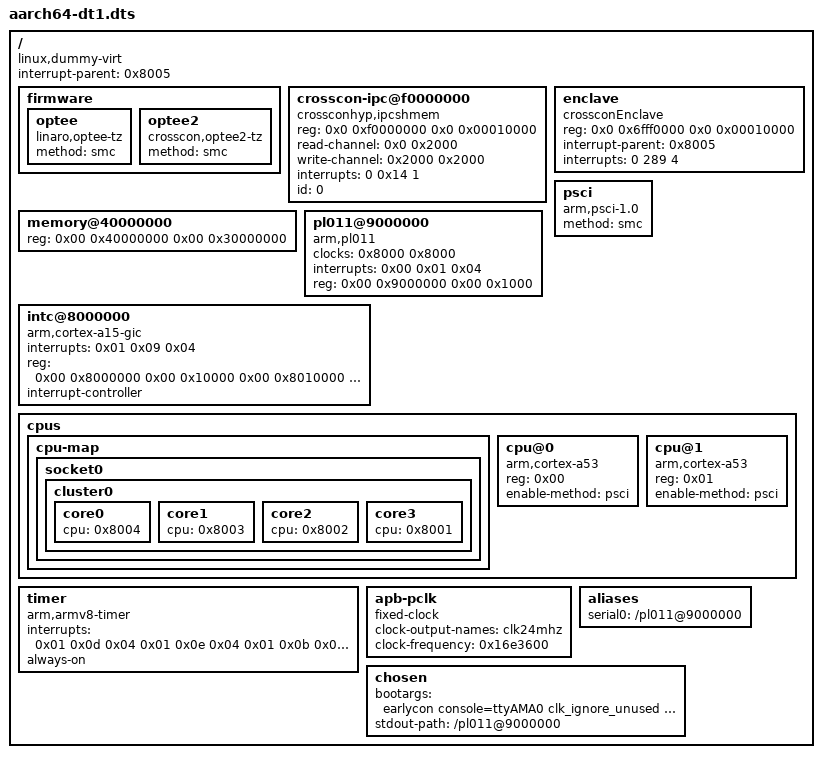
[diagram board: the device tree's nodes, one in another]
/dts-v1/;

/ {
	interrupt-parent = <0x8005>;
	#size-cells = <0x02>;
	#address-cells = <0x02>;
	compatible = "linux,dummy-virt";

	firmware {
		optee {
			compatible = "linaro,optee-tz";
			method = "smc";
		};
                optee2 {
			compatible = "crosscon,optee2-tz";
			method = "smc";
		};
        };

        crosscon-ipc@f0000000 {
            compatible = "crossconhyp,ipcshmem";
            reg = <0x0 0xf0000000 0x0 0x00010000>;
            read-channel = <0x0 0x2000>;
            write-channel = <0x2000 0x2000>;
            interrupts = <0 0x14 1>;
            id = <0>;
        };

        enclave{
            compatible = "crossconEnclave";
            #address-cells = <2>;
            #size-cells = <2>;
            reg = <0x0 0x6fff0000 0x0 0x00010000>;
            interrupt-parent = <0x8005>;
            interrupts = <0 289 4>; //(32*(8+1))+1       + 32
        };

        psci {
		compatible = "arm,psci-1.0";
		method = "smc";
	};


	memory@40000000 {
		reg = <0x00 0x40000000 0x00 0x30000000>;
		device_type = "memory";
	};

	pl011@9000000 {
		clock-names = "uartclk\0apb_pclk";
		clocks = <0x8000 0x8000>;
		interrupts = <0x00 0x01 0x04>;
		reg = <0x00 0x9000000 0x00 0x1000>;
		compatible = "arm,pl011\0arm,primecell";
	};

	// pmu {
	// 	interrupts = <0x1 0x7 0xf04>;
	// 	compatible = "arm,armv8-pmuv3";
	// };

	intc@8000000 {
		phandle = <0x8005>;
		interrupts = <0x01 0x09 0x04>;
		reg = <0x00 0x8000000 0x00 0x10000 0x00 0x8010000 0x00 0x10000 0x00 0x8030000 0x00 0x10000 0x00 0x8040000 0x00 0x10000>;
		compatible = "arm,cortex-a15-gic";
		ranges;
		#size-cells = <0x02>;
		#address-cells = <0x02>;
		interrupt-controller;
		#interrupt-cells = <0x03>;


	};

	/* intc@8000000 { */
	/* 	phandle = <0x8005>; */
	/* 	interrupts = <0x01 0x09 0x04>; */
	/* 	reg = <0x00 0x8000000 0x00 0x10000 0x00 0x80a0000 0x00 0xf60000>; */
	/* 	#redistributor-regions = <0x01>; */
	/* 	compatible = "arm,gic-v3"; */
	/* 	ranges; */
	/* 	#size-cells = <0x02>; */
	/* 	#address-cells = <0x02>; */
	/* 	interrupt-controller; */
	/* 	#interrupt-cells = <0x03>; */

	/* 	its@8080000 { */
	/* 		phandle = <0x8006>; */
	/* 		reg = <0x00 0x8080000 0x00 0x20000>; */
	/* 		msi-controller; */
	/* 		compatible = "arm,gic-v3-its"; */
	/* 	}; */
	/* }; */

	cpus {
		#size-cells = <0x00>;
		#address-cells = <0x01>;

		cpu-map {

			socket0 {

				cluster0 {

					core0 {
						cpu = <0x8004>;
					};

					core1 {
						cpu = <0x8003>;
					};

					core2 {
						cpu = <0x8002>;
					};

					core3 {
						cpu = <0x8001>;
					};
				};
			};
		};

		cpu@0 {
			phandle = <0x8004>;
			reg = <0x00>;
			compatible = "arm,cortex-a53";
			device_type = "cpu";
                        enable-method = "psci";
		};

		cpu@1 {
			phandle = <0x8003>;
			reg = <0x01>;
			compatible = "arm,cortex-a53";
			device_type = "cpu";
                        enable-method = "psci";
		};

		/* cpu@2 { */
		/* 	phandle = <0x8002>; */
		/* 	reg = <0x02>; */
		/* 	compatible = "arm,cortex-a53"; */
		/* 	device_type = "cpu"; */
                        /* enable-method = "psci"; */
		/* }; */

		/* cpu@3 { */
		/* 	phandle = <0x8001>; */
		/* 	reg = <0x03>; */
		/* 	compatible = "arm,cortex-a53"; */
		/* 	device_type = "cpu"; */
                        /* enable-method = "psci"; */
		/* }; */
	};

	timer {
		interrupts = <0x01 0x0d 0x04 0x01 0x0e 0x04 0x01 0x0b 0x04 0x01 0x0a 0x04>;
		always-on;
		compatible = "arm,armv8-timer\0arm,armv7-timer";
	};

	apb-pclk {
		phandle = <0x8000>;
		clock-output-names = "clk24mhz";
		clock-frequency = <0x16e3600>;
		#clock-cells = <0x00>;
		compatible = "fixed-clock";
	};


	aliases {
		serial0 = "/pl011@9000000";
	};

	chosen {
		bootargs = "earlycon console=ttyAMA0 clk_ignore_unused init=/sbin/init";
		stdout-path = "/pl011@9000000";
	};
};
